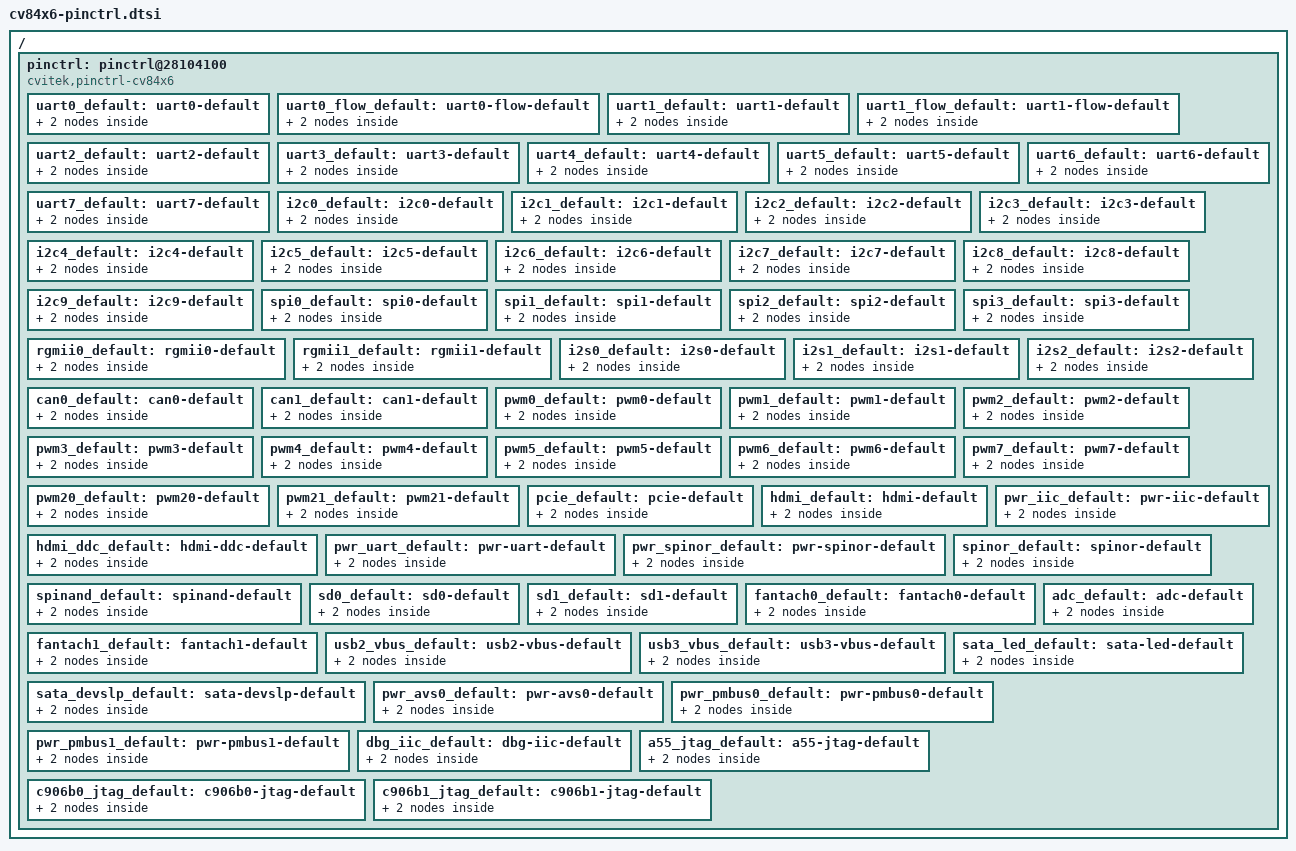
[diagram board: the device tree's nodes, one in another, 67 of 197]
// SPDX-License-Identifier: GPL-2.0
/*
 * CV84x6 pinctrl controller device tree include
 *
 * This file defines the pinctrl controller node and pre-built pin states
 * for common peripherals.  Board-level DTS files should include this file
 * and then reference the pin states from their device nodes.
 *
 * Usage in board DTS:
 *
 *   #include "cv84x6-pinctrl.dtsi"
 *
 *   &uart0 {
 *       pinctrl-names = "default";
 *       pinctrl-0 = <&uart0_default>;
 *   };
 */

/ {
	pinctrl: pinctrl@28104100 {
		compatible = "cvitek,pinctrl-cv84x6";
		/*
		 * Register regions: G1, G2, G3, G4, G7, G8
		 * Must match the order expected by the driver
		 * (CV84X6_RES_G1=0 .. CV84X6_RES_G8=5)
		 */
		reg = <0x0 0x28104100 0x0 0x100>,   /* G1: PCIE */
		      <0x0 0x28104200 0x0 0x100>,   /* G2: UART */
		      <0x0 0x28104300 0x0 0x100>,   /* G3: USB/SATA/GPIO/SD/HDMI/PWM/RGMII_MDIO/I2C/ADC */
		      <0x0 0x28104e00 0x0 0x100>,   /* G4: RGMII_DATA/SPI/I2S/SPINOR */
		      <0x0 0x05027000 0x0 0x100>,   /* G7: PWR_UART (RTC domain) */
		      <0x0 0x05027800 0x0 0x100>;   /* G8: PWR domain */

		/*
		 * ============================================================
		 * Pre-defined pin states for common peripherals
		 *
		 * Each state has two sub-nodes:
		 *   - mux:  selects the pin function (groups + function)
		 *   - cfg:  configures electrical properties (optional)
		 *
		 * To add custom pin states, follow the same pattern.
		 * ============================================================
		 */

		/* --- UART --- */
		uart0_default: uart0-default {
			mux {
				groups = "uart0_grp";
				function = "uart0";
			};
			cfg {
				pins = "UART0_TX", // UART0_TX -> UART0_TX (mux=0)
			       "UART0_RX"; // UART0_RX -> UART0_RX (mux=0)
				bias-pull-up;
				drive-strength = <4>;
			};
		};

		uart0_flow_default: uart0-flow-default {
			mux {
				groups = "uart0_flow_grp";
				function = "uart0";
			};
			cfg {
				pins = "UART0_TX", // UART0_TX -> UART0_TX (mux=0)
			       "UART0_RX", // UART0_RX -> UART0_RX (mux=0)
			       "UART0_CTS", // UART0_CTS -> UART0_CTS (mux=0)
			       "UART0_RTS"; // UART0_RTS -> UART0_RTS (mux=0)
				bias-pull-up;
				drive-strength = <4>;
			};
		};

		uart1_default: uart1-default {
			mux {
				groups = "uart1_grp";
				function = "uart1";
			};
			cfg {
				pins = "UART1_TX", // UART1_TX -> UART1_TX (mux=0)
			       "UART1_RX"; // UART1_RX -> UART1_RX (mux=0)
				bias-pull-up;
				drive-strength = <4>;
			};
		};

		uart1_flow_default: uart1-flow-default {
			mux {
				groups = "uart1_flow_grp";
				function = "uart1";
			};
			cfg {
				pins = "UART1_TX", // UART1_TX -> UART1_TX (mux=0)
			       "UART1_RX", // UART1_RX -> UART1_RX (mux=0)
			       "UART1_CTS", // UART1_CTS -> UART1_CTS (mux=0)
			       "UART1_RTS"; // UART1_RTS -> UART1_RTS (mux=0)
				bias-pull-up;
				drive-strength = <4>;
			};
		};

		uart2_default: uart2-default {
			mux {
				groups = "uart2_grp";
				function = "uart2";
			};
			cfg {
				pins = "UART2_TX", // UART2_TX -> UART2_TX (mux=0)
			       "UART2_RX"; // UART2_RX -> UART2_RX (mux=0)
				bias-pull-up;
				drive-strength = <4>;
			};
		};

		uart3_default: uart3-default {
			mux {
				groups = "uart3_grp";
				function = "uart3";
			};
			cfg {
				pins = "UART1_CTS", // UART1_CTS -> UART3_TX (mux=2)
			       "UART1_RTS"; // UART1_RTS -> UART3_RX (mux=2)
				bias-pull-up;
				drive-strength = <4>;
			};
		};

		uart4_default: uart4-default {
			mux {
				groups = "uart4_grp";
				function = "uart4";
			};
			cfg {
				pins = "GPIO2", // GPIO2 -> UART4_TX (mux=2)
			       "GPIO3"; // GPIO3 -> UART4_RX (mux=2)
				bias-pull-up;
				drive-strength = <4>;
			};
		};

		uart5_default: uart5-default {
			mux {
				groups = "uart5_grp";
				function = "uart5";
			};
			cfg {
				pins = "SD1_PWR_EN", // SD1_PWR_EN -> UART5_TX (mux=1)
			       "SD1_CD_X"; // SD1_CD_X -> UART5_RX (mux=1)
				bias-pull-up;
				drive-strength = <4>;
			};
		};

		uart6_default: uart6-default {
			mux {
				groups = "uart6_grp";
				function = "uart6";
			};
			cfg {
				pins = "GPIO6", // GPIO6 -> UART6_TX (mux=2)
			       "GPIO7"; // GPIO7 -> UART6_RX (mux=2)
				bias-pull-up;
				drive-strength = <4>;
			};
		};

		uart7_default: uart7-default {
			mux {
				groups = "uart7_grp";
				function = "uart7";
			};
			cfg {
				pins = "SD0_PWR_EN", // SD0_PWR_EN -> UART7_TX (mux=1)
			       "SD0_CD_X"; // SD0_CD_X -> UART7_RX (mux=1)
				bias-pull-up;
				drive-strength = <4>;
			};
		};

		/* --- I2C --- */
		i2c0_default: i2c0-default {
			mux {
				groups = "i2c0_grp";
				function = "i2c0";
			};
			cfg {
				pins = "IIC0_SDA", // IIC0_SDA -> IIC0_SDA (mux=0)
			       "IIC0_SCL"; // IIC0_SCL -> IIC0_SCL (mux=0)
				bias-pull-up;
				drive-strength = <4>;
				input-schmitt-enable;
			};
		};

		i2c1_default: i2c1-default {
			mux {
				groups = "i2c1_grp";
				function = "i2c1";
			};
			cfg {
				pins = "IIC1_SDA", // IIC1_SDA -> IIC1_SDA (mux=0)
			       "IIC1_SCL"; // IIC1_SCL -> IIC1_SCL (mux=0)
				bias-pull-up;
				drive-strength = <4>;
				input-schmitt-enable;
			};
		};

		i2c2_default: i2c2-default {
			mux {
				groups = "i2c2_grp";
				function = "i2c2";
			};
			cfg {
				pins = "IIC2_SDA", // IIC2_SDA -> IIC2_SDA (mux=0)
			       "IIC2_SCL"; // IIC2_SCL -> IIC2_SCL (mux=0)
				bias-pull-up;
				drive-strength = <4>;
				input-schmitt-enable;
			};
		};

		i2c3_default: i2c3-default {
			mux {
				groups = "i2c3_grp";
				function = "i2c3";
			};
			cfg {
				pins = "IIC3_SDA", // IIC3_SDA -> IIC3_SDA (mux=0)
			       "IIC3_SCL"; // IIC3_SCL -> IIC3_SCL (mux=0)
				bias-pull-up;
				drive-strength = <4>;
				input-schmitt-enable;
			};
		};

		i2c4_default: i2c4-default {
			mux {
				groups = "i2c4_grp";
				function = "i2c4";
			};
			cfg {
				pins = "GPIO0", // GPIO0 -> IIC4_SDA (mux=1)
			       "GPIO1"; // GPIO1 -> IIC4_SCL (mux=1)
				bias-pull-up;
				drive-strength = <4>;
				input-schmitt-enable;
			};
		};

		i2c5_default: i2c5-default {
			mux {
				groups = "i2c5_grp";
				function = "i2c5";
			};
			cfg {
				pins = "HDMI_DDC_SDA", // HDMI_DDC_SDA -> IIC5_SDA (mux=1)
			       "HDMI_DDC_SCL"; // HDMI_DDC_SCL -> IIC5_SCL (mux=1)
				bias-pull-up;
				drive-strength = <4>;
				input-schmitt-enable;
			};
		};

		i2c6_default: i2c6-default {
			mux {
				groups = "i2c6_grp";
				function = "i2c6";
			};
			cfg {
				pins = "RGMII1_MDC", // RGMII1_MDC -> IIC6_SCL (mux=1)
			       "RGMII1_MDIO"; // RGMII1_MDIO -> IIC6_SDA (mux=1)
				bias-pull-up;
				drive-strength = <4>;
				input-schmitt-enable;
			};
		};

		i2c7_default: i2c7-default {
			mux {
				groups = "i2c7_grp";
				function = "i2c7";
			};
			cfg {
				pins = "PWM0", // PWM0 -> IIC7_SDA (mux=2)
			       "PWM1"; // PWM1 -> IIC7_SCL (mux=2)
				bias-pull-up;
				drive-strength = <4>;
				input-schmitt-enable;
			};
		};

		i2c8_default: i2c8-default {
			mux {
				groups = "i2c8_grp";
				function = "i2c8";
			};
			cfg {
				pins = "PWM2", // PWM2 -> IIC8_SDA (mux=2)
			       "PWM3"; // PWM3 -> IIC8_SCL (mux=2)
				bias-pull-up;
				drive-strength = <4>;
				input-schmitt-enable;
			};
		};

		i2c9_default: i2c9-default {
			mux {
				groups = "i2c9_grp";
				function = "i2c9";
			};
			cfg {
				pins = "RGMII0_MDC", // RGMII0_MDC -> IIC9_SCL (mux=1)
			       "RGMII0_MDIO"; // RGMII0_MDIO -> IIC9_SDA (mux=1)
				bias-pull-up;
				drive-strength = <4>;
				input-schmitt-enable;
			};
		};

		/* --- SPI --- */
		spi0_default: spi0-default {
			mux {
				groups = "spi0_grp";
				function = "spi0";
			};
			cfg {
				pins = "SPI0_CS0_X", // SPI0_CS0_X -> SPI0_CS0_X (mux=0)
			       "SPI0_CS1_X", // SPI0_CS1_X -> SPI0_CS1_X (mux=0)
			       "SPI0_SDI", // SPI0_SDI -> SPI0_SDI (mux=0)
			       "SPI0_SDO", // SPI0_SDO -> SPI0_SDO (mux=0)
			       "SPI0_SCK"; // SPI0_SCK -> SPI0_SCK (mux=0)
				drive-strength = <8>;
			};
		};

		spi1_default: spi1-default {
			mux {
				groups = "spi1_grp";
				function = "spi1";
			};
			cfg {
				pins = "RGMII0_TXD0", // RGMII0_TXD0 -> SPI1_SCK (mux=2)
			       "RGMII0_TXD1", // RGMII0_TXD1 -> SPI1_CS0_X (mux=2)
			       "RGMII0_TXD2", // RGMII0_TXD2 -> SPI1_CS1_X (mux=2)
			       "RGMII0_RXD0", // RGMII0_RXD0 -> SPI1_SDO (mux=2)
			       "RGMII0_RXD1"; // RGMII0_RXD1 -> SPI1_SDI (mux=2)
				drive-strength = <8>;
			};
		};

		spi2_default: spi2-default {
			mux {
				groups = "spi2_grp";
				function = "spi2";
			};
			cfg {
				pins = "RGMII0_TXD3", // RGMII0_TXD3 -> SPI2_SDO (mux=1)
			       "RGMII0_TXCTRL", // RGMII0_TXCTRL -> SPI2_SDI (mux=1)
			       "RGMII0_RXD2", // RGMII0_RXD2 -> SPI2_SCK (mux=2)
			       "RGMII0_RXD3", // RGMII0_RXD3 -> SPI2_CS0_X (mux=2)
			       "RGMII0_RXCTRL"; // RGMII0_RXCTRL -> SPI2_CS1_X (mux=2)
				drive-strength = <8>;
			};
		};

		spi3_default: spi3-default {
			mux {
				groups = "spi3_grp";
				function = "spi3";
			};
			cfg {
				pins = "RGMII1_TXD0", // RGMII1_TXD0 -> SPI3_SCK (mux=2)
			       "RGMII1_TXD1", // RGMII1_TXD1 -> SPI3_CS0_X (mux=2)
			       "RGMII1_TXD2", // RGMII1_TXD2 -> SPI3_CS1_X (mux=2)
			       "RGMII1_RXD0", // RGMII1_RXD0 -> SPI3_SDO (mux=2)
			       "RGMII1_RXD1"; // RGMII1_RXD1 -> SPI3_SDI (mux=2)
				drive-strength = <8>;
			};
		};

		/* --- RGMII --- */
		rgmii0_default: rgmii0-default {
			mux {
				groups = "rgmii0_grp";
				function = "rgmii0";
			};
			cfg {
				pins = "RGMII0_TXD0", // RGMII0_TXD0 -> RGMII0_TXD0 (mux=0)
			       "RGMII0_TXD1", // RGMII0_TXD1 -> RGMII0_TXD1 (mux=0)
			       "RGMII0_TXD2", // RGMII0_TXD2 -> RGMII0_TXD2 (mux=0)
			       "RGMII0_TXD3", // RGMII0_TXD3 -> RGMII0_TXD3 (mux=0)
			       "RGMII0_TXCTRL", // RGMII0_TXCTRL -> RGMII0_TXCTRL (mux=0)
			       "RGMII0_RXD0", // RGMII0_RXD0 -> RGMII0_RXD0 (mux=0)
			       "RGMII0_RXD1", // RGMII0_RXD1 -> RGMII0_RXD1 (mux=0)
			       "RGMII0_RXD2", // RGMII0_RXD2 -> RGMII0_RXD2 (mux=0)
			       "RGMII0_RXD3", // RGMII0_RXD3 -> RGMII0_RXD3 (mux=0)
			       "RGMII0_RXCTRL", // RGMII0_RXCTRL -> RGMII0_RXCTRL (mux=0)
			       "RGMII0_TXC", // RGMII0_TXC -> RGMII0_TXC (mux=0)
			       "RGMII0_RXC", // RGMII0_RXC -> RGMII0_RXC (mux=0)
			       "RGMII0_REFCLKO", // RGMII0_REFCLKO -> RGMII0_REFCLKO (mux=0)
			       "RGMII0_IRQ", // RGMII0_IRQ -> RGMII0_IRQ (mux=0)
			       "RGMII0_MDC", // RGMII0_MDC -> RGMII0_MDC (mux=0)
			       "RGMII0_MDIO"; // RGMII0_MDIO -> RGMII0_MDIO (mux=0)
				drive-strength = <8>;
			};
		};

		rgmii1_default: rgmii1-default {
			mux {
				groups = "rgmii1_grp";
				function = "rgmii1";
			};
			cfg {
				pins = "RGMII1_TXD0", // RGMII1_TXD0 -> RGMII1_TXD0 (mux=0)
			       "RGMII1_TXD1", // RGMII1_TXD1 -> RGMII1_TXD1 (mux=0)
			       "RGMII1_TXD2", // RGMII1_TXD2 -> RGMII1_TXD2 (mux=0)
			       "RGMII1_TXD3", // RGMII1_TXD3 -> RGMII1_TXD3 (mux=0)
			       "RGMII1_TXCTRL", // RGMII1_TXCTRL -> RGMII1_TXCTRL (mux=0)
			       "RGMII1_RXD0", // RGMII1_RXD0 -> RGMII1_RXD0 (mux=0)
			       "RGMII1_RXD1", // RGMII1_RXD1 -> RGMII1_RXD1 (mux=0)
			       "RGMII1_RXD2", // RGMII1_RXD2 -> RGMII1_RXD2 (mux=0)
			       "RGMII1_RXD3", // RGMII1_RXD3 -> RGMII1_RXD3 (mux=0)
			       "RGMII1_RXCTRL", // RGMII1_RXCTRL -> RGMII1_RXCTRL (mux=0)
			       "RGMII1_TXC", // RGMII1_TXC -> RGMII1_TXC (mux=0)
			       "RGMII1_RXC", // RGMII1_RXC -> RGMII1_RXC (mux=0)
			       "RGMII1_REFCLKO", // RGMII1_REFCLKO -> RGMII1_REFCLKO (mux=0)
			       "RGMII1_IRQ", // RGMII1_IRQ -> RGMII1_IRQ (mux=0)
			       "RGMII1_MDC", // RGMII1_MDC -> RGMII1_MDC (mux=0)
			       "RGMII1_MDIO"; // RGMII1_MDIO -> RGMII1_MDIO (mux=0)
				drive-strength = <8>;
			};
		};

		/* --- I2S --- */
		i2s0_default: i2s0-default {
			mux {
				groups = "i2s0_grp";
				function = "i2s0";
			};
			cfg {
				pins = "I2S0_SCLK", // I2S0_SCLK -> I2S0_SCLK (mux=0)
			       "I2S0_WSI", // I2S0_WSI -> I2S0_WSI (mux=0)
			       "I2S0_SDI0", // I2S0_SDI0 -> I2S0_SDI0 (mux=0)
			       "I2S0_SDI1", // I2S0_SDI1 -> I2S0_SDI1 (mux=0)
			       "I2S0_SDO", // I2S0_SDO -> I2S0_SDO (mux=0)
			       "I2S0_MCLK"; // I2S0_MCLK -> I2S0_MCLK (mux=0)
				drive-strength = <4>;
			};
		};

		i2s1_default: i2s1-default {
			mux {
				groups = "i2s1_grp";
				function = "i2s1";
			};
			cfg {
				pins = "SPI0_CS0_X", // SPI0_CS0_X -> I2S1_SCLK (mux=1)
			       "SPI0_CS1_X", // SPI0_CS1_X -> I2S1_WSI (mux=1)
			       "SPI0_SDI", // SPI0_SDI -> I2S1_SDI (mux=1)
			       "SPI0_SDO", // SPI0_SDO -> I2S1_SDO (mux=1)
			       "SPI0_SCK"; // SPI0_SCK -> I2S1_MCLK (mux=1)
				drive-strength = <4>;
			};
		};

		i2s2_default: i2s2-default {
			mux {
				groups = "i2s2_grp";
				function = "i2s2";
			};
			cfg {
				pins = "IIC1_SCL", // IIC1_SCL -> I2S2_MCLK (mux=2)
			       "IIC2_SDA", // IIC2_SDA -> I2S2_SCLK (mux=2)
			       "IIC2_SCL", // IIC2_SCL -> I2S2_WSI (mux=2)
			       "IIC3_SDA", // IIC3_SDA -> I2S2_SDI (mux=2)
			       "IIC3_SCL"; // IIC3_SCL -> I2S2_SDO (mux=2)
				drive-strength = <4>;
			};
		};
		//i2s1_default: i2s1-default {
		//	mux {
		//		groups = "i2s1_grp";
		//		function = "i2s1";
		//	};
		//	cfg {
		//		pins = "SPI0_CS0_X", "SPI0_CS1_X",
		//				"SPI0_SDI","SPI0_SDO",
		//				"SPI0_SCK";
		//		drive-strength = <4>;
		//	};
		//};
		//i2s2_default: i2s2-default {
		//	mux {
		//		groups = "i2s2_grp";
		//		function = "i2s2";
		//	};
		//	cfg {
		//		pins = "IIC2_SDA", "IIC2_SCL",
		//				"IIC3_SDA","IIC3_SCL",
		//				"IIC1_SCL";
		//		drive-strength = <4>;
		//	};
		//};

		/* --- CAN --- */
		can0_default: can0-default {
			mux {
				groups = "can0_grp";
				function = "can0";
			};
			cfg {
				pins = "PWM2", // PWM2 -> CAN0_TX (mux=1)
			       "PWM3"; // PWM3 -> CAN0_RX (mux=1)
				drive-strength = <4>;
			};
		};

		can1_default: can1-default {
			mux {
				groups = "can1_grp";
				function = "can1";
			};
			cfg {
				pins = "SD1_PWR_EN", // SD1_PWR_EN -> CAN1_TX (mux=2)
			       "SD1_CD_X"; // SD1_CD_X -> CAN1_RX (mux=2)
				drive-strength = <4>;
			};
		};

		/* --- PWM --- */
		pwm0_default: pwm0-default {
			mux {
				groups = "pwm0_grp";
				function = "pwm0";
			};
			cfg {
				pins = "PWM0"; // PWM0 -> PWM0 (mux=0)
				drive-strength = <4>;
			};
		};

		pwm1_default: pwm1-default {
			mux {
				groups = "pwm1_grp";
				function = "pwm1";
			};
			cfg {
				pins = "PWM1"; // PWM1 -> PWM1 (mux=0)
				drive-strength = <4>;
			};
		};

		pwm2_default: pwm2-default {
			mux {
				groups = "pwm2_grp";
				function = "pwm2";
			};
			cfg {
				pins = "PWM2"; // PWM2 -> PWM2 (mux=0)
				drive-strength = <4>;
			};
		};

		pwm3_default: pwm3-default {
			mux {
				groups = "pwm3_grp";
				function = "pwm3";
			};
			cfg {
				pins = "PWM3"; // PWM3 -> PWM3 (mux=0)
				drive-strength = <4>;
			};
		};

		pwm4_default: pwm4-default {
			mux {
				groups = "pwm4_grp";
				function = "pwm4";
			};
			cfg {
				pins = "FANTACH0"; // FANTACH0 -> PWM4 (mux=2)
				drive-strength = <4>;
			};
		};

		pwm5_default: pwm5-default {
			mux {
				groups = "pwm5_grp";
				function = "pwm5";
			};
			cfg {
				pins = "FANTACH1"; // FANTACH1 -> PWM5 (mux=2)
				drive-strength = <4>;
			};
		};

		pwm6_default: pwm6-default {
			mux {
				groups = "pwm6_grp";
				function = "pwm6";
			};
			cfg {
				pins = "UART1_TX"; // UART1_TX -> PWM6 (mux=2)
				drive-strength = <4>;
			};
		};

		pwm7_default: pwm7-default {
			mux {
				groups = "pwm7_grp";
				function = "pwm7";
			};
			cfg {
				pins = "UART1_RX"; // UART1_RX -> PWM7 (mux=2)
				drive-strength = <4>;
			};
		};

		pwm20_default: pwm20-default {
			mux {
				groups = "pwm20_grp";
				function = "pwm20";
			};
			cfg {
				pins = "USB2_VBUS_EN0"; // USB2_VBUS_EN0 -> PWM20 (mux=1)
				drive-strength = <4>;
			};
		};

		pwm21_default: pwm21-default {
			mux {
				groups = "pwm21_grp";
				function = "pwm21";
			};
			cfg {
				pins = "USB2_VBUS_EN1"; // USB2_VBUS_EN1 -> PWM21 (mux=1)
				drive-strength = <4>;
			};
		};

		/* --- PCIE --- */
		pcie_default: pcie-default {
			mux {
				groups = "pcie_grp";
				function = "pcie";
			};
			cfg {
				pins = "PCIE0_RESET_X", // PCIE0_RESET_X -> PCIE0_RESET_X (mux=0)
			       "PCIE1_RESET_X", // PCIE1_RESET_X -> PCIE1_RESET_X (mux=0)
			       "PCIE2_RESET_X", // PCIE2_RESET_X -> PCIE2_RESET_X (mux=0)
			       "PCIE3_RESET_X", // PCIE3_RESET_X -> PCIE3_RESET_X (mux=0)
			       "PCIE_CLKREQ_IN_X", // PCIE_CLKREQ_IN_X -> PCIE_CLKREQ_IN_X (mux=0)
			       "PCIE_WAKEUP_X"; // PCIE_WAKEUP_X -> PCIE_WAKEUP_X (mux=0)
				drive-strength = <4>;
			};
		};

		/* --- HDMI --- */
		hdmi_default: hdmi-default {
			mux {
				groups = "hdmi_grp";
				function = "hdmi";
			};
			cfg {
				pins = "HDMI_DDC_SDA", // HDMI_DDC_SDA -> HDMI_DDC_SDA (mux=0)
			       "HDMI_DDC_SCL"; // HDMI_DDC_SCL -> HDMI_DDC_SCL (mux=0)
				bias-pull-up;
				input-schmitt-enable;
			};
		};

		hdmi_ddc_default: hdmi-ddc-default {
			mux {
				groups = "hdmi_ddc_grp";
				function = "hdmi";
			};
			cfg {
				pins = "HDMI_DDC_SDA", // HDMI_DDC_SDA -> HDMI_DDC_SDA (mux=0)
			       "HDMI_DDC_SCL"; // HDMI_DDC_SCL -> HDMI_DDC_SCL (mux=0)
				bias-pull-up;
				input-schmitt-enable;
			};
		};

		/* --- PWR domain UART --- */
		pwr_uart_default: pwr-uart-default {
			mux {
				groups = "pwr_uart_grp";
				function = "pwr_uart";
			};
			cfg {
				pins = "PWR_UART_TX", // PWR_UART_TX -> PWR_UART_TX (mux=0)
			       "PWR_UART_RX"; // PWR_UART_RX -> PWR_UART_RX (mux=0)
				bias-pull-up;
				drive-strength = <4>;
			};
		};

		/* --- PWR domain I2C --- */
		pwr_iic_default: pwr-iic-default {
			mux {
				groups = "pwr_iic_grp";
				function = "pwr_iic";
			};
			cfg {
				pins = "PWR_IIC_SDA", // PWR_IIC_SDA -> PWR_IIC_SDA (mux=0)
			       "PWR_IIC_SCL"; // PWR_IIC_SCL -> PWR_IIC_SCL (mux=0)
				bias-pull-up;
				drive-strength = <4>;
				input-schmitt-enable;
			};
		};

		pwr_spinor_default: pwr-spinor-default {
			mux {
				groups = "pwr_spinor_grp";
				function = "pwr_spinor";
			};
			cfg {
				pins = "PWR_GPIO0", // PWR_GPIO0 -> PWR_SPINOR_HOLD_X (mux=0)
			       "PWR_GPIO1", // PWR_GPIO1 -> PWR_SPINOR_WP_X (mux=0)
			       "PWR_GPIO2", // PWR_GPIO2 -> PWR_SPINOR_CS_X (mux=0)
			       "PWR_GPIO3", // PWR_GPIO3 -> PWR_SPINOR_SDI (mux=0)
			       "PWR_GPIO4", // PWR_GPIO4 -> PWR_SPINOR_SDO (mux=0)
			       "PWR_GPIO5"; // PWR_GPIO5 -> PWR_SPINOR_SCK (mux=0)
				drive-strength = <8>;
			};
		};

		/* --- SPINOR (via I2S0 pins) --- */
		spinor_default: spinor-default {
			mux {
				groups = "spinor_grp";
				function = "spinor";
			};
			cfg {
				pins = "I2S0_SCLK", // I2S0_SCLK -> SPINOR_CS_X (mux=1)
			       "I2S0_WSI", // I2S0_WSI -> SPINOR_SDI (mux=1)
			       "I2S0_SDI0", // I2S0_SDI0 -> SPINOR_SDO (mux=1)
			       "I2S0_SDI1", // I2S0_SDI1 -> SPINOR_WP_X (mux=1)
			       "I2S0_SDO", // I2S0_SDO -> SPINOR_HOLD_X (mux=1)
			       "I2S0_MCLK"; // I2S0_MCLK -> SPINOR_SCK (mux=1)
				drive-strength = <8>;
			};
		};

		/* --- SPINAND (via I2S0 pins) --- */
		spinand_default: spinand-default {
			mux {
				groups = "spinand_grp";
				function = "spinand";
			};
			cfg {
				pins = "I2S0_SCLK", // I2S0_SCLK -> SPINAND_CS_X (mux=2)
			       "I2S0_WSI", // I2S0_WSI -> SPINAND_SDI (mux=2)
			       "I2S0_SDI0", // I2S0_SDI0 -> SPINAND_SDO (mux=2)
			       "I2S0_SDI1", // I2S0_SDI1 -> SPINAND_WP_X (mux=2)
			       "I2S0_SDO", // I2S0_SDO -> SPINAND_HOLD_X (mux=2)
			       "I2S0_MCLK"; // I2S0_MCLK -> SPINAND_SCK (mux=2)
				drive-strength = <8>;
			};
		};

		/* --- SD card --- */
		sd0_default: sd0-default {
			mux {
				groups = "sd0_grp";
				function = "sd0";
			};
			cfg {
				pins = "SD0_PWR_EN", // SD0_PWR_EN -> SD0_PWR_EN (mux=0)
			       "SD0_CD_X"; // SD0_CD_X -> SD0_CD_X (mux=0)
				bias-pull-up;
			};
		};

		sd1_default: sd1-default {
			mux {
				groups = "sd1_grp";
				function = "sd1";
			};
			cfg {
				pins = "SD1_PWR_EN", // SD1_PWR_EN -> SD1_PWR_EN (mux=0)
			       "SD1_CD_X"; // SD1_CD_X -> SD1_CD_X (mux=0)
				bias-pull-up;
			};
		};

		/* --- FAN tach --- */
		fantach0_default: fantach0-default {
			mux {
				groups = "fantach0_grp";
				function = "fantach0";
			};
			cfg {
				pins = "FANTACH0"; // FANTACH0 -> FANTACH0 (mux=0)
				drive-strength = <4>;
			};
		};

		fantach1_default: fantach1-default {
			mux {
				groups = "fantach1_grp";
				function = "fantach1";
			};
			cfg {
				pins = "FANTACH1"; // FANTACH1 -> FANTACH1 (mux=0)
				drive-strength = <4>;
			};
		};

		/* --- ADC --- */
		adc_default: adc-default {
			mux {
				groups = "adc_grp";
				function = "adc";
			};
			cfg {
				pins = "ADC1", // ADC1 -> ADC1 (mux=0)
			       "ADC2", // ADC2 -> ADC2 (mux=0)
			       "ADC3"; // ADC3 -> ADC3 (mux=0)
			};
		};

		/* --- USB VBUS --- */
		usb2_vbus_default: usb2-vbus-default {
			mux {
				groups = "usb2_vbus_grp";
				function = "usb2_vbus";
			};
			cfg {
				pins = "USB2_VBUS_EN0", // USB2_VBUS_EN0 -> USB2_VBUS_EN0 (mux=0)
			       "USB2_VBUS_EN1"; // USB2_VBUS_EN1 -> USB2_VBUS_EN1 (mux=0)
				drive-strength = <4>;
			};
		};

		usb3_vbus_default: usb3-vbus-default {
			mux {
				groups = "usb3_vbus_grp";
				function = "usb3_vbus";
			};
			cfg {
				pins = "USB3_VBUS_EN0", // USB3_VBUS_EN0 -> USB3_VBUS_EN0 (mux=0)
			       "USB3_VBUS_EN1"; // USB3_VBUS_EN1 -> USB3_VBUS_EN1 (mux=0)
				drive-strength = <4>;
			};
		};

		/* --- SATA --- */
		sata_devslp_default: sata-devslp-default {
			mux {
				groups = "sata_devslp_grp";
				function = "sata_devslp";
			};
			cfg {
				pins = "SATA_DEVSLP0", // SATA_DEVSLP0 -> SATA_DEVSLP0 (mux=0)
			       "SATA_DEVSLP1", // SATA_DEVSLP1 -> SATA_DEVSLP1 (mux=0)
			       "SATA_DEVSLP2", // SATA_DEVSLP2 -> SATA_DEVSLP2 (mux=0)
			       "SATA_DEVSLP3"; // SATA_DEVSLP3 -> SATA_DEVSLP3 (mux=0)
				drive-strength = <4>;
			};
		};

		sata_led_default: sata-led-default {
			mux {
				groups = "sata_led_grp";
				function = "sata_led";
			};
			cfg {
				pins = "SATA_LED0", // SATA_LED0 -> SATA_LED0 (mux=0)
			       "SATA_LED1", // SATA_LED1 -> SATA_LED1 (mux=0)
			       "SATA_LED2", // SATA_LED2 -> SATA_LED2 (mux=0)
			       "SATA_LED3"; // SATA_LED3 -> SATA_LED3 (mux=0)
				drive-strength = <4>;
			};
		};

		/* --- PWR domain AVS/PMBUS --- */
		pwr_avs0_default: pwr-avs0-default {
			mux {
				groups = "pwr_avs0_grp";
				function = "pwr_avs0";
			};
			cfg {
				pins = "PWR_AVS0_CLK", // PWR_AVS0_CLK -> PWR_AVS0_CLK (mux=0)
			       "PWR_AVS0_SDI", // PWR_AVS0_SDI -> PWR_AVS0_SDI (mux=0)
			       "PWR_AVS0_SDO"; // PWR_AVS0_SDO -> PWR_AVS0_SDO (mux=0)
				drive-strength = <4>;
			};
		};

		pwr_pmbus0_default: pwr-pmbus0-default {
			mux {
				groups = "pwr_pmbus0_grp";
				function = "pwr_pmbus0";
			};
			cfg {
				pins = "PWR_PMBUS_ALERT", // PWR_PMBUS_ALERT -> PWR_PMBUS0_ALERT (mux=0)
			       "PWR_PMBUS_SCL", // PWR_PMBUS_SCL -> PWR_PMBUS0_SCL (mux=0)
			       "PWR_PMBUS_SDA"; // PWR_PMBUS_SDA -> PWR_PMBUS0_SDA (mux=0)
				bias-pull-up;
				drive-strength = <4>;
				input-schmitt-enable;
			};
		};

		pwr_pmbus1_default: pwr-pmbus1-default {
			mux {
				groups = "pwr_pmbus1_grp";
				function = "pwr_pmbus1";
			};
			cfg {
				pins = "PWR_AVS0_CLK", // PWR_AVS0_CLK -> PWR_PMBUS1_ALERT (mux=1)
			       "PWR_AVS0_SDI", // PWR_AVS0_SDI -> PWR_PMBUS1_SCL (mux=1)
			       "PWR_AVS0_SDO"; // PWR_AVS0_SDO -> PWR_PMBUS1_SDA (mux=1)
				bias-pull-up;
				drive-strength = <4>;
				input-schmitt-enable;
			};
		};

		/* --- Debug / JTAG --- */
		dbg_iic_default: dbg-iic-default {
			mux {
				groups = "dbg_iic_grp";
				function = "dbg_iic";
			};
			cfg {
				pins = "GPIO6", // GPIO6 -> DBG_IIC_SDA (mux=1)
			       "GPIO7"; // GPIO7 -> DBG_IIC_SCL (mux=1)
				bias-pull-up;
				drive-strength = <4>;
				input-schmitt-enable;
			};
		};

		a55_jtag_default: a55-jtag-default {
			mux {
				groups = "a55_jtag_grp";
				function = "a55_jtag";
			};
			cfg {
				pins = "GPIO0", // GPIO0 -> A55_JTAG_TDO (mux=0)
			       "GPIO1", // GPIO1 -> A55_JTAG_TCK (mux=0)
			       "GPIO2", // GPIO2 -> A55_JTAG_TDI (mux=0)
			       "GPIO3", // GPIO3 -> A55_JTAG_TMS (mux=0)
			       "GPIO4", // GPIO4 -> A55_JTAG_TRST_X (mux=0)
			       "GPIO5"; // GPIO5 -> A55_JTAG_SRST_X (mux=0)
				drive-strength = <4>;
			};
		};

		c906b0_jtag_default: c906b0-jtag-default {
			mux {
				groups = "c906b0_jtag_grp";
				function = "c906b0_jtag";
			};
			cfg {
				pins = "IIC1_SDA", // IIC1_SDA -> C906B0_JTAG_TDO (mux=1)
			       "IIC1_SCL", // IIC1_SCL -> C906B0_JTAG_TDI (mux=1)
			       "IIC2_SDA", // IIC2_SDA -> C906B0_JTAG_TCK (mux=1)
			       "IIC2_SCL", // IIC2_SCL -> C906B0_JTAG_TMS (mux=1)
			       "IIC3_SDA", // IIC3_SDA -> C906B0_JTAG_TRST_X (mux=1)
			       "IIC3_SCL"; // IIC3_SCL -> C906B0_JTAG_SRST_X (mux=1)
				drive-strength = <4>;
			};
		};

		c906b1_jtag_default: c906b1-jtag-default {
			mux {
				groups = "c906b1_jtag_grp";
				function = "c906b1_jtag";
			};
			cfg {
				pins = "UART1_TX", // UART1_TX -> C906B1_JTAG_TDO (mux=1)
			       "UART1_RX", // UART1_RX -> C906B1_JTAG_TCK (mux=1)
			       "UART1_CTS", // UART1_CTS -> C906B1_JTAG_TDI (mux=1)
			       "UART1_RTS", // UART1_RTS -> C906B1_JTAG_TMS (mux=1)
			       "UART2_TX", // UART2_TX -> C906B1_JTAG_TRST_X (mux=1)
			       "UART2_RX"; // UART2_RX -> C906B1_JTAG_SRST_X (mux=1)
				drive-strength = <4>;
			};
		};
	};
};
